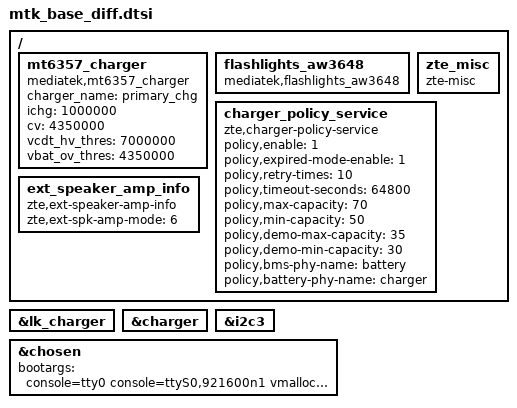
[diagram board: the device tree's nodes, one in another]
/*
 * when you want to delete some nodes or property, modify this dtsi.
 * some diff between mtk and zte pluto.
 */

/{
	mt6357_charger {
		compatible = "mediatek,mt6357_charger";
		status="okay";
		charger_name = "primary_chg";
		ichg = <1000000>;	/* uA */
		cv = <4350000>;		/* uV */
		vcdt_hv_thres = <7000000>;
		vbat_ov_thres = <4350000>;		/* uV */
	};
	/*add for Z3351S flash chip node*/
	flashlights_aw3648: flashlights_aw3648 {
		compatible = "mediatek,flashlights_aw3648";
	};

	zte_misc: zte_misc {
		status="okay";
		compatible = "zte-misc";
	};

	charger_policy_service {
		compatible = "zte,charger-policy-service";
		status="okay";
		policy,enable = <1>;
		policy,expired-mode-enable = <1>;
		policy,retry-times = <10>;
		policy,timeout-seconds = <64800>;/* 18 hours */
		policy,max-capacity = <70>;
		policy,min-capacity = <50>;
		policy,demo-max-capacity = <35>;
		policy,demo-min-capacity = <30>;
		policy,bms-phy-name = "battery";
		policy,battery-phy-name = "charger";
	};
	ext_speaker_amp_info {
		status="okay";
		compatible = "zte,ext-speaker-amp-info";
		zte,ext-spk-amp-mode = <6>;
	};
};

&lk_charger {
	/delete-property/ enable_pe_plus;
};

&charger {
	/delete-property/ enable_pe_plus;
	/delete-property/ enable_pe_2;
	/delete-property/ enable_pe_3;
	/delete-property/ enable_pe_4;
	/delete-property/ enable_type_c;
	/delete-property/ power_path_support;
};

/ {
	/delete-node/ mt6370_pmu_dts;
};

/ {
	/delete-node/ type_c_port0;
};

&i2c3 {
	/delete-node/ rt9465@4b;
};

/* chosen */
&chosen {
	bootargs = "console=tty0 console=ttyS0,921600n1 \
vmalloc=400M slub_max_order=0 slub_debug=OFZPU \
page_owner=on androidboot.hardware=mt6761 \
maxcpus=8 firmware_class.path=/vendor/firmware loop.max_part=7";
};
